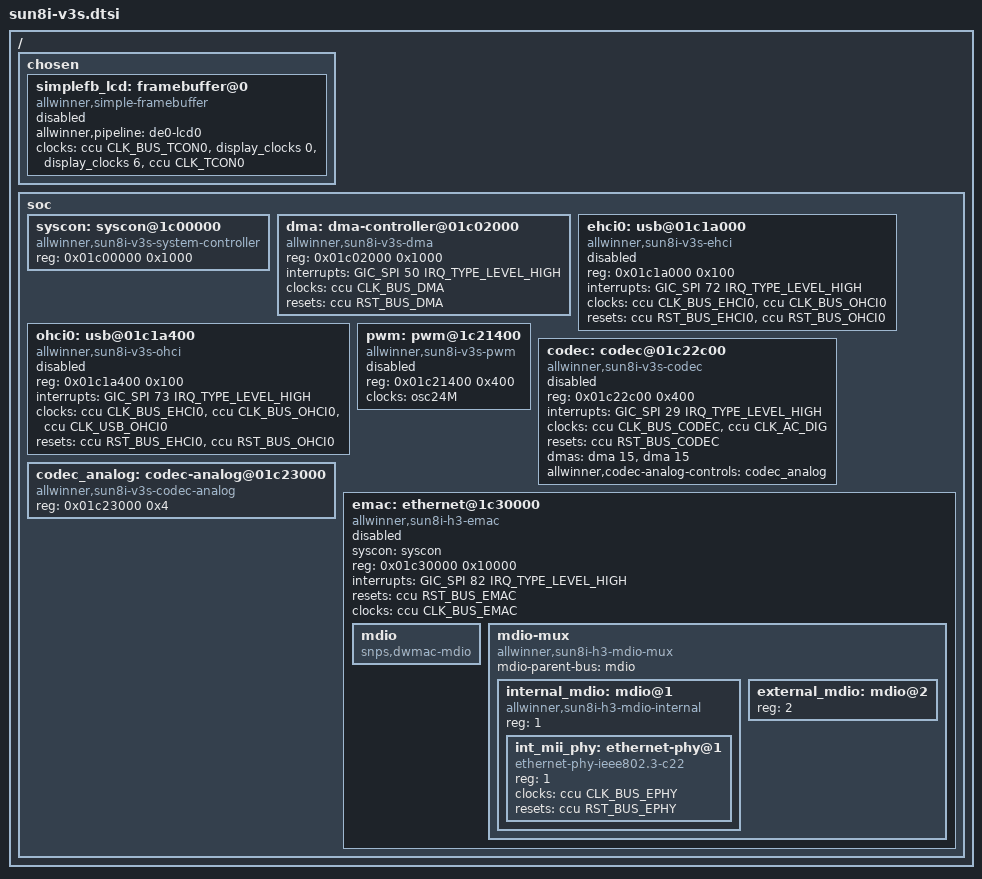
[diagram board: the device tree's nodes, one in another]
/* $NetBSD$ */

/*-
 * Copyright (c) 2021 Rui-Xiang Guo
 * All rights reserved.
 *
 * Redistribution and use in source and binary forms, with or without
 * modification, are permitted provided that the following conditions
 * are met:
 * 1. Redistributions of source code must retain the above copyright
 *    notice, this list of conditions and the following disclaimer.
 * 2. Redistributions in binary form must reproduce the above copyright
 *    notice, this list of conditions and the following disclaimer in the
 *    documentation and/or other materials provided with the distribution.
 *
 * THIS SOFTWARE IS PROVIDED BY THE AUTHOR ``AS IS'' AND ANY EXPRESS OR
 * IMPLIED WARRANTIES, INCLUDING, BUT NOT LIMITED TO, THE IMPLIED WARRANTIES
 * OF MERCHANTABILITY AND FITNESS FOR A PARTICULAR PURPOSE ARE DISCLAIMED.
 * IN NO EVENT SHALL THE AUTHOR BE LIABLE FOR ANY DIRECT, INDIRECT,
 * INCIDENTAL, SPECIAL, EXEMPLARY, OR CONSEQUENTIAL DAMAGES (INCLUDING,
 * BUT NOT LIMITED TO, PROCUREMENT OF SUBSTITUTE GOODS OR SERVICES;
 * LOSS OF USE, DATA, OR PROFITS; OR BUSINESS INTERRUPTION) HOWEVER CAUSED
 * AND ON ANY THEORY OF LIABILITY, WHETHER IN CONTRACT, STRICT LIABILITY,
 * OR TORT (INCLUDING NEGLIGENCE OR OTHERWISE) ARISING IN ANY WAY
 * OUT OF THE USE OF THIS SOFTWARE, EVEN IF ADVISED OF THE POSSIBILITY OF
 * SUCH DAMAGE.
 */

/ {
	chosen {
		#address-cells = <1>;
		#size-cells = <1>;
		ranges;

		simplefb_lcd: framebuffer@0 {
			compatible = "allwinner,simple-framebuffer",
				     "simple-framebuffer";
			allwinner,pipeline = "de0-lcd0";
			clocks = <&ccu CLK_BUS_TCON0>, <&display_clocks 0>,
				 <&display_clocks 6>, <&ccu CLK_TCON0>;
			status = "disabled";
		};
	};

	soc {
		syscon: syscon@1c00000 {
			compatible = "allwinner,sun8i-v3s-system-controller",
				"syscon";
			reg = <0x01c00000 0x1000>;
		};

		dma: dma-controller@01c02000 {
			compatible = "allwinner,sun8i-v3s-dma";
			reg = <0x01c02000 0x1000>;
			interrupts = <GIC_SPI 50 IRQ_TYPE_LEVEL_HIGH>;
			clocks = <&ccu CLK_BUS_DMA>;
			resets = <&ccu RST_BUS_DMA>;
			#dma-cells = <1>;
		};

		ehci0: usb@01c1a000 {
			compatible = "allwinner,sun8i-v3s-ehci", "generic-ehci";
			reg = <0x01c1a000 0x100>;
			interrupts = <GIC_SPI 72 IRQ_TYPE_LEVEL_HIGH>;
			clocks = <&ccu CLK_BUS_EHCI0>, <&ccu CLK_BUS_OHCI0>;
			resets = <&ccu RST_BUS_EHCI0>, <&ccu RST_BUS_OHCI0>;
			status = "disabled";
		};

		ohci0: usb@01c1a400 {
			compatible = "allwinner,sun8i-v3s-ohci", "generic-ohci";
			reg = <0x01c1a400 0x100>;
			interrupts = <GIC_SPI 73 IRQ_TYPE_LEVEL_HIGH>;
			clocks = <&ccu CLK_BUS_EHCI0>, <&ccu CLK_BUS_OHCI0>,
				 <&ccu CLK_USB_OHCI0>;
			resets = <&ccu RST_BUS_EHCI0>, <&ccu RST_BUS_OHCI0>;
			status = "disabled";
		};

		pwm: pwm@1c21400 {
			compatible = "allwinner,sun8i-v3s-pwm",
				     "allwinner,sun7i-a20-pwm";
			reg = <0x01c21400 0x400>;
			clocks = <&osc24M>;
			#pwm-cells = <3>;
			status = "disabled";
		};

		codec: codec@01c22c00 {
			#sound-dai-cells = <0>;
			compatible = "allwinner,sun8i-v3s-codec";
			reg = <0x01c22c00 0x400>;
			interrupts = <GIC_SPI 29 IRQ_TYPE_LEVEL_HIGH>;
			clocks = <&ccu CLK_BUS_CODEC>, <&ccu CLK_AC_DIG>;
			clock-names = "apb", "codec";
			resets = <&ccu RST_BUS_CODEC>;
			dmas = <&dma 15>, <&dma 15>;
			dma-names = "rx", "tx";
			allwinner,codec-analog-controls = <&codec_analog>;
			status = "disabled";
		};

		codec_analog: codec-analog@01c23000 {
			compatible = "allwinner,sun8i-v3s-codec-analog";
			reg = <0x01c23000 0x4>;
		};

		emac: ethernet@1c30000 {
			compatible = "allwinner,sun8i-h3-emac";
			syscon = <&syscon>;
			reg = <0x01c30000 0x10000>;
			interrupts = <GIC_SPI 82 IRQ_TYPE_LEVEL_HIGH>;
			interrupt-names = "macirq";
			resets = <&ccu RST_BUS_EMAC>;
			reset-names = "stmmaceth";
			clocks = <&ccu CLK_BUS_EMAC>;
			clock-names = "stmmaceth";
			status = "disabled";

			mdio: mdio {
				#address-cells = <1>;
				#size-cells = <0>;
				compatible = "snps,dwmac-mdio";
			};

			mdio-mux {
				compatible = "allwinner,sun8i-h3-mdio-mux";
				#address-cells = <1>;
				#size-cells = <0>;

				mdio-parent-bus = <&mdio>;
				/* Only one MDIO is usable at the time */
				internal_mdio: mdio@1 {
					compatible = "allwinner,sun8i-h3-mdio-internal";
					reg = <1>;
					#address-cells = <1>;
					#size-cells = <0>;

					int_mii_phy: ethernet-phy@1 {
						compatible = "ethernet-phy-ieee802.3-c22";
						reg = <1>;
						clocks = <&ccu CLK_BUS_EPHY>;
						resets = <&ccu RST_BUS_EPHY>;
					};
				};

				external_mdio: mdio@2 {
					reg = <2>;
					#address-cells = <1>;
					#size-cells = <0>;
				};
			};
		};
	};
};
